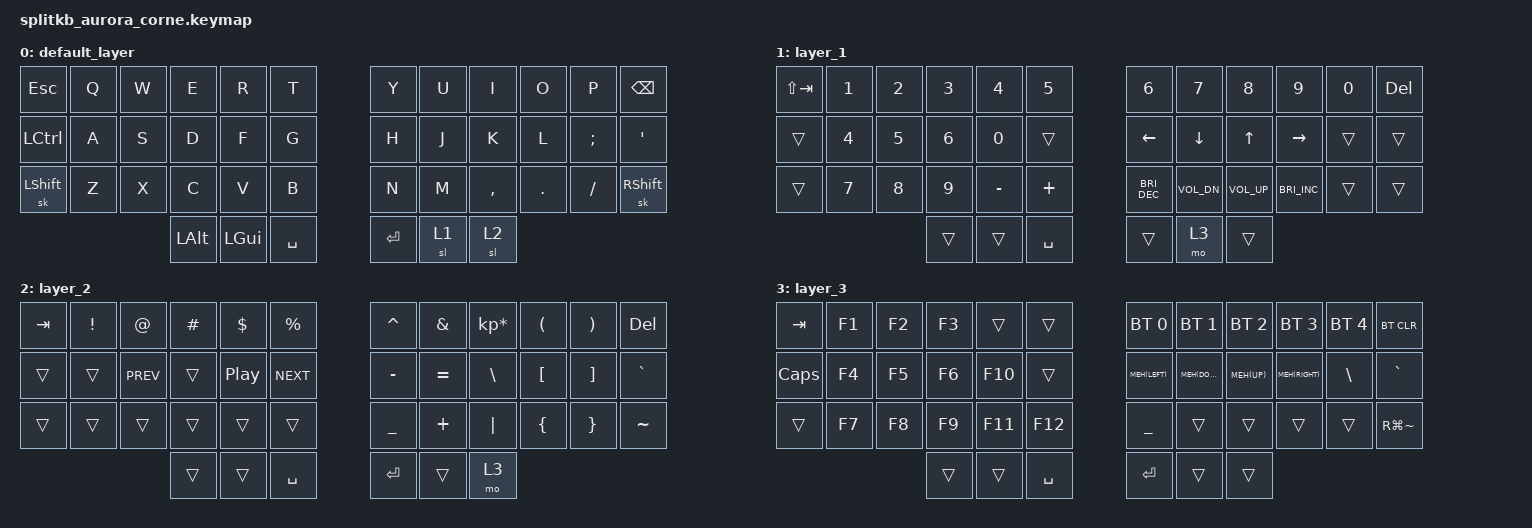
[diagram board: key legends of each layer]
/*
 * Copyright (c) 2020 The ZMK Contributors
 *
 * SPDX-License-Identifier: MIT
 */


#include <behaviors.dtsi>
#include <dt-bindings/zmk/keys.h>
#include <dt-bindings/zmk/bt.h>

// * Enable Mouse Keys
#include <dt-bindings/zmk/mouse.h>
#include <dt-bindings/zmk/mouse_settings.h>
#include "includes/mouse_keys.dtsi"

#define MEH(k1) &kp RG(RA(k1))

&mt {
       tapping-term-ms = <150>;
    };

&sk {
       release-after-ms = <150>;
       quick-release;
    };

&sl {
       release-after-ms = <150>;
    };

/ {
        keymap {
                compatible = "zmk,keymap";

                default_layer {
                        bindings = <
   &kp ESC       &kp Q    &kp W    &kp E    &kp R    &kp T                        &kp Y   &kp U  &kp I     &kp O   &kp P    &kp BSPC
   &kp LCTRL     &kp A    &kp S    &kp D    &kp F    &kp G                        &kp H   &kp J  &kp K     &kp L   &kp SEMI &kp SQT
   &sk LSHFT     &kp Z    &kp X    &kp C    &kp V    &kp B                        &kp N   &kp M  &kp COMMA &kp DOT &kp FSLH &sk RSHFT
                               &kp LALT &kp LGUI &kp SPACE                        &kp RET &sl 1  &sl 2
                        >;
                };

                layer_1 {
                        bindings = <
   &kp LS(TAB) &kp N1       &kp N2       &kp N3       &kp N4     &kp N5            &kp N6          &kp N7           &kp N8       &kp N9         &kp N0   &kp DEL
   &trans      &kp N4       &kp N5       &kp N6       &kp N0     &trans            &kp LEFT        &kp DOWN         &kp UP       &kp RIGHT      &trans   &trans
   &trans      &kp N7       &kp N8       &kp N9       &kp MINUS  &kp PLUS          &kp C_BRI_DEC   &kp C_VOL_DN     &kp C_VOL_UP &kp C_BRI_INC  &trans   &trans
                          	         &trans       &trans     &kp SPACE         &trans          &mo 3            &trans
                        >;
                };

                layer_2 {
                        bindings = <
   &kp TAB   &kp EXCL &kp AT       &kp HASH &kp DLLR &kp PRCNT                          &kp CARET &kp AMPS  &kp KP_MULTIPLY &kp LPAR  &kp RPAR &kp DEL
   &trans    &trans   &kp C_PREV   &trans   &kp C_PP &kp C_NEXT                         &kp MINUS &kp EQUAL &kp BSLH        &kp LBKT  &kp RBKT &kp GRAVE
   &trans    &trans   &trans       &trans   &trans   &trans                             &kp UNDER &kp PLUS  &kp PIPE        &kp LBRC  &kp RBRC &kp TILDE
                    	           &trans   &trans   &kp SPACE                          &kp RET   &trans    &mo 3
                        >;
                };

                layer_3 {
                        bindings = <
   &kp TAB   &kp F1   &kp F2 &kp F3   &trans    &trans                            &bt BT_SEL 0    &bt BT_SEL 1    &bt BT_SEL 2    &bt BT_SEL 3    &bt BT_SEL 4       &bt BT_CLR
   &kp CAPS  &kp F4   &kp F5 &kp F6   &kp F10   &trans                            MEH(LEFT)       MEH(DOWN)       MEH(UP)         MEH(RIGHT)      &kp BSLH           &kp GRAVE
   &trans    &kp F7   &kp F8 &kp F9   &kp F11   &kp F12                           &kp UNDER       &trans          &trans          &trans          &trans             &kp RG(TILDE)
                    	     &trans   &trans   &kp SPACE                          &kp RET         &trans          &trans
                        >;
                };
        };
};
